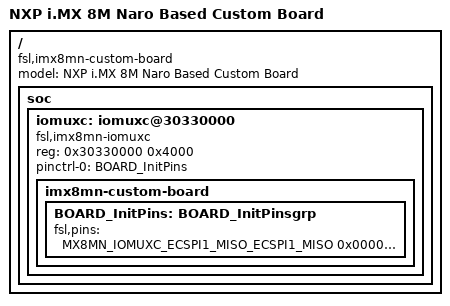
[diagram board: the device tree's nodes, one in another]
/***********************************************************************************************************************
 * This file was generated by the MCUXpresso Config Tools. Any manual edits made to this file
 * will be overwritten if the respective MCUXpresso Config Tools is used to update this file.
 **********************************************************************************************************************/

/*
 * TEXT BELOW IS USED AS SETTING FOR TOOLS *************************************
!!GlobalInfo
product: Pins v11.0
processor: MIMX8MN4xxxIZ
package_id: MIMX8MN4CVTIZ
mcu_data: ksdk2_0
processor_version: 11.0.1
power_domains: {NVCC_CLK: '1.8', NVCC_DRAM: '1.1', NVCC_ECSPI: '1.8', NVCC_ENET: '1.8', NVCC_GPIO1: '1.8', NVCC_I2C: '1.8', NVCC_JTAG: '1.8', NVCC_NAND: '1.8', NVCC_SAI2: '1.8',
  NVCC_SAI3: '1.8', NVCC_SAI5: '1.8', NVCC_SD1: '1.8', NVCC_SD2: '1.8', NVCC_SNVS_1P8: '1.8', NVCC_UART: '1.8', VDD_ANA1_1P8: '1.8', VDD_MIPI_1P8: '1.8', VDD_USB_1P8: '1.8',
  VDD_USB_3P3: '3.3'}
 * BE CAREFUL MODIFYING THIS COMMENT - IT IS YAML SETTINGS FOR TOOLS ***********
 */


/dts-v1/;

#include "skeleton.dtsi"
#include "pins-imx8mn.h"

/ {
    model = "NXP i.MX 8M Naro Based Custom Board";
    compatible = "fsl,imx8mn-custom-board", "fsl,imx8mn-evk", "fsl,imx8mn";

    soc {
        #address-cells = <1>;
        #size-cells = <1>;

        iomuxc: iomuxc@30330000 {
            compatible = "fsl,imx8mn-iomuxc";
            reg = <0x30330000 0x4000>;
        };
    };
};

&iomuxc {
    pinctrl-names = "default_iomuxc";
    pinctrl-0 = <&BOARD_InitPins>;


    imx8mn-custom-board {
        BOARD_InitPins: BOARD_InitPinsgrp {                /*!< Function assigned for the core: Cortex-A53[a53_0] */
/*
 * TEXT BELOW IS USED AS SETTING FOR TOOLS *************************************
BOARD_InitPins:
- options: {callFromInitBoot: 'false', coreID: a53_0}
- pin_list:
  - {pin_num: B27, peripheral: XTALOSC, signal: xtalosc_xtal_in_24m, pin_signal: XTALI_24M}
  - {pin_num: P27, peripheral: uSDHC3, signal: usdhc_strobe, pin_signal: NAND_CE1_B}
  - {pin_num: M27, peripheral: uSDHC3, signal: 'usdhc_data, 5', pin_signal: NAND_CE2_B}
  - {pin_num: L27, peripheral: uSDHC3, signal: 'usdhc_data, 6', pin_signal: NAND_CE3_B}
  - {pin_num: K27, peripheral: uSDHC3, signal: 'usdhc_data, 7', pin_signal: NAND_CLE}
  - {pin_num: N27, peripheral: uSDHC3, signal: 'usdhc_data, 4', pin_signal: NAND_RE_B}
  - {pin_num: R26, peripheral: uSDHC3, signal: usdhc_clk, pin_signal: NAND_WE_B}
  - {pin_num: R27, peripheral: uSDHC3, signal: usdhc_cmd, pin_signal: NAND_WP_B}
  - {pin_num: M26, peripheral: uSDHC3, signal: 'usdhc_data, 0', pin_signal: NAND_DATA04}
  - {pin_num: L26, peripheral: uSDHC3, signal: 'usdhc_data, 1', pin_signal: NAND_DATA05}
  - {pin_num: K26, peripheral: uSDHC3, signal: 'usdhc_data, 2', pin_signal: NAND_DATA06}
  - {pin_num: N26, peripheral: uSDHC3, signal: 'usdhc_data, 3', pin_signal: NAND_DATA07}
  - {pin_num: W23, peripheral: uSDHC2, signal: usdhc_clk, pin_signal: SD2_CLK}
  - {pin_num: W24, peripheral: uSDHC2, signal: usdhc_cmd, pin_signal: SD2_CMD}
  - {pin_num: AB23, peripheral: uSDHC2, signal: 'usdhc_data, 0', pin_signal: SD2_DATA0}
  - {pin_num: AB24, peripheral: uSDHC2, signal: 'usdhc_data, 1', pin_signal: SD2_DATA1}
  - {pin_num: V24, peripheral: uSDHC2, signal: 'usdhc_data, 2', pin_signal: SD2_DATA2}
  - {pin_num: V23, peripheral: uSDHC2, signal: 'usdhc_data, 3', pin_signal: SD2_DATA3}
  - {pin_num: AA27, peripheral: uSDHC2, signal: usdhc_wp, pin_signal: SD2_WP}
  - {pin_num: AA26, peripheral: uSDHC2, signal: usdhc_cd_b, pin_signal: SD2_CD_B}
  - {pin_num: Y27, peripheral: uSDHC1, signal: 'usdhc_data, 0', pin_signal: SD1_DATA0}
  - {pin_num: V27, peripheral: uSDHC1, signal: usdhc_cmd, pin_signal: SD1_CMD}
  - {pin_num: Y26, peripheral: uSDHC1, signal: 'usdhc_data, 1', pin_signal: SD1_DATA1}
  - {pin_num: T26, peripheral: uSDHC1, signal: 'usdhc_data, 3', pin_signal: SD1_DATA3}
  - {pin_num: T27, peripheral: uSDHC1, signal: 'usdhc_data, 2', pin_signal: SD1_DATA2}
  - {pin_num: U27, peripheral: uSDHC1, signal: 'usdhc_data, 4', pin_signal: SD1_DATA4}
  - {pin_num: U26, peripheral: uSDHC1, signal: 'usdhc_data, 5', pin_signal: SD1_DATA5}
  - {pin_num: W27, peripheral: uSDHC1, signal: 'usdhc_data, 6', pin_signal: SD1_DATA6}
  - {pin_num: W26, peripheral: uSDHC1, signal: 'usdhc_data, 7', pin_signal: SD1_DATA7}
  - {pin_num: V26, peripheral: uSDHC1, signal: usdhc_clk, pin_signal: SD1_CLK}
  - {pin_num: AG11, peripheral: uSDHC1, signal: usdhc_cd_b, pin_signal: GPIO1_IO06}
  - {pin_num: AF11, peripheral: uSDHC1, signal: usdhc_wp, pin_signal: GPIO1_IO07}
  - {pin_num: F26, peripheral: CJTAG, signal: jtag_tck, pin_signal: JTAG_TCK}
  - {pin_num: E27, peripheral: CJTAG, signal: jtag_tdi, pin_signal: JTAG_TDI}
  - {pin_num: E26, peripheral: CJTAG, signal: jtag_tdo, pin_signal: JTAG_TDO}
  - {pin_num: F27, peripheral: CJTAG, signal: jtag_tms, pin_signal: JTAG_TMS}
  - {pin_num: C27, peripheral: CJTAG, signal: jtag_trst_b, pin_signal: BOOT_MODE2}
  - {pin_num: E9, peripheral: I2C1, signal: i2c_scl, pin_signal: I2C1_SCL}
  - {pin_num: F9, peripheral: I2C1, signal: i2c_sda, pin_signal: I2C1_SDA}
  - {pin_num: D9, peripheral: I2C2, signal: i2c_sda, pin_signal: I2C2_SDA}
  - {pin_num: D10, peripheral: I2C2, signal: i2c_scl, pin_signal: I2C2_SCL}
  - {pin_num: F10, peripheral: I2C3, signal: i2c_sda, pin_signal: I2C3_SDA}
  - {pin_num: E10, peripheral: I2C3, signal: i2c_scl, pin_signal: I2C3_SCL}
  - {pin_num: AE27, peripheral: ENET1, signal: 'enet_rgmii_rd, 0', pin_signal: ENET_RD0}
  - {pin_num: AD27, peripheral: ENET1, signal: 'enet_rgmii_rd, 1', pin_signal: ENET_RD1}
  - {pin_num: AD26, peripheral: ENET1, signal: 'enet_rgmii_rd, 2', pin_signal: ENET_RD2}
  - {pin_num: AC26, peripheral: ENET1, signal: 'enet_rgmii_rd, 3', pin_signal: ENET_RD3}
  - {pin_num: AF26, peripheral: ENET1, signal: 'enet_rgmii_td, 1', pin_signal: ENET_TD1}
  - {pin_num: AG25, peripheral: ENET1, signal: 'enet_rgmii_td, 2', pin_signal: ENET_TD2}
  - {pin_num: AF25, peripheral: ENET1, signal: 'enet_rgmii_td, 3', pin_signal: ENET_TD3}
  - {pin_num: AG26, peripheral: ENET1, signal: 'enet_rgmii_td, 0', pin_signal: ENET_TD0}
  - {pin_num: AG24, peripheral: ENET1, signal: enet_rgmii_txc, pin_signal: ENET_TXC}
  - {pin_num: AF24, peripheral: ENET1, signal: enet_rgmii_tx_ctl, pin_signal: ENET_TX_CTL}
  - {pin_num: AF27, peripheral: ENET1, signal: enet_rgmii_rx_ctl, pin_signal: ENET_RX_CTL}
  - {pin_num: AE26, peripheral: ENET1, signal: enet_rgmii_rxc, pin_signal: ENET_RXC}
  - {pin_num: AC27, peripheral: ENET1, signal: enet_mdc, pin_signal: ENET_MDC}
  - {pin_num: AB27, peripheral: ENET1, signal: enet_mdio, pin_signal: ENET_MDIO}
  - {pin_num: A22, peripheral: USB1, signal: usb_dn, pin_signal: USB1_DN}
  - {pin_num: B22, peripheral: USB1, signal: usb_dp, pin_signal: USB1_DP}
  - {peripheral: USB2, signal: usb_dp, pin_signal: USB2_DP}
  - {peripheral: USB2, signal: usb_dn, pin_signal: USB2_DN}
  - {peripheral: USB2, signal: usb_id, pin_signal: USB2_ID}
  - {pin_num: AD9, peripheral: USB1, signal: usb_otg_oc, pin_signal: GPIO1_IO13}
  - {pin_num: AB10, peripheral: USB1, signal: usb_otg_pwr, pin_signal: GPIO1_IO12}
  - {pin_num: F22, peripheral: USB1, signal: usb_vbus, pin_signal: USB1_VBUS}
  - {pin_num: D22, peripheral: USB1, signal: usb_id, pin_signal: USB1_ID}
  - {peripheral: USB2, signal: usb_vbus, pin_signal: USB2_VBUS}
  - {pin_num: AC9, peripheral: USB2, signal: usb_otg_pwr, pin_signal: GPIO1_IO14}
  - {pin_num: AB9, peripheral: USB2, signal: usb_otg_oc, pin_signal: GPIO1_IO15}
  - {pin_num: A7, peripheral: ECSPI1, signal: ecspi_miso, pin_signal: ECSPI1_MISO}
  - {pin_num: B7, peripheral: ECSPI1, signal: ecspi_mosi, pin_signal: ECSPI1_MOSI}
  - {pin_num: D6, peripheral: ECSPI1, signal: ecspi_sclk, pin_signal: ECSPI1_SCLK, PE: Enabled}
  - {pin_num: B6, peripheral: ECSPI1, signal: 'ecspi_ss, 0', pin_signal: ECSPI1_SS0}
  - {pin_num: N22, peripheral: QSPI, signal: qspi_a_sclk, pin_signal: NAND_ALE}
  - {pin_num: N24, peripheral: QSPI, signal: qspi_a_ss0_b, pin_signal: NAND_CE0_B}
  - {pin_num: P23, peripheral: QSPI, signal: 'qspi_a_data, 0', pin_signal: NAND_DATA00}
  - {pin_num: K24, peripheral: QSPI, signal: 'qspi_a_data, 1', pin_signal: NAND_DATA01}
  - {pin_num: K23, peripheral: QSPI, signal: 'qspi_a_data, 2', pin_signal: NAND_DATA02}
  - {pin_num: N23, peripheral: QSPI, signal: 'qspi_a_data, 3', pin_signal: NAND_DATA03}
  - {pin_num: A16, peripheral: MIPI_CSI, signal: mipi_csi_clk_n, pin_signal: MIPI_CSI_CLK_N}
  - {pin_num: B16, peripheral: MIPI_CSI, signal: mipi_csi_clk_p, pin_signal: MIPI_CSI_CLK_P}
  - {pin_num: A14, peripheral: MIPI_CSI, signal: mipi_csi_d0_n, pin_signal: MIPI_CSI_D0_N}
  - {pin_num: B14, peripheral: MIPI_CSI, signal: mipi_csi_d0_p, pin_signal: MIPI_CSI_D0_P}
  - {pin_num: A15, peripheral: MIPI_CSI, signal: mipi_csi_d1_n, pin_signal: MIPI_CSI_D1_N}
  - {pin_num: B15, peripheral: MIPI_CSI, signal: mipi_csi_d1_p, pin_signal: MIPI_CSI_D1_P}
  - {pin_num: A17, peripheral: MIPI_CSI, signal: mipi_csi_d2_n, pin_signal: MIPI_CSI_D2_N}
  - {pin_num: B17, peripheral: MIPI_CSI, signal: mipi_csi_d2_p, pin_signal: MIPI_CSI_D2_P}
  - {pin_num: A18, peripheral: MIPI_CSI, signal: mipi_csi_d3_n, pin_signal: MIPI_CSI_D3_N}
  - {pin_num: B18, peripheral: MIPI_CSI, signal: mipi_csi_d3_p, pin_signal: MIPI_CSI_D3_P}
  - {pin_num: A11, peripheral: MIPI_DSI, signal: mipi_dsi_clk_n, pin_signal: MIPI_DSI_CLK_N}
  - {pin_num: B11, peripheral: MIPI_DSI, signal: mipi_dsi_clk_p, pin_signal: MIPI_DSI_CLK_P}
  - {pin_num: A9, peripheral: MIPI_DSI, signal: mipi_dsi_d0_n, pin_signal: MIPI_DSI_D0_N}
  - {pin_num: B9, peripheral: MIPI_DSI, signal: mipi_dsi_d0_p, pin_signal: MIPI_DSI_D0_P}
  - {pin_num: A10, peripheral: MIPI_DSI, signal: mipi_dsi_d1_n, pin_signal: MIPI_DSI_D1_N}
  - {pin_num: B10, peripheral: MIPI_DSI, signal: mipi_dsi_d1_p, pin_signal: MIPI_DSI_D1_P}
  - {pin_num: A12, peripheral: MIPI_DSI, signal: mipi_dsi_d2_n, pin_signal: MIPI_DSI_D2_N}
  - {pin_num: B12, peripheral: MIPI_DSI, signal: mipi_dsi_d2_p, pin_signal: MIPI_DSI_D2_P}
  - {pin_num: A13, peripheral: MIPI_DSI, signal: mipi_dsi_d3_n, pin_signal: MIPI_DSI_D3_N}
  - {pin_num: B13, peripheral: MIPI_DSI, signal: mipi_dsi_d3_p, pin_signal: MIPI_DSI_D3_P}
  - {pin_num: D15, peripheral: MIPI_DSI, signal: mipi_dsi_rext, pin_signal: MIPI_VREG_CAP}
  - {peripheral: PCIE1, signal: pcie_rxn_n, pin_signal: PCIE_RXN_N}
  - {peripheral: PCIE1, signal: pcie_rxn_p, pin_signal: PCIE_RXN_P}
  - {peripheral: PCIE1, signal: pcie_txn_n, pin_signal: PCIE_TXN_N}
  - {peripheral: PCIE1, signal: pcie_txn_p, pin_signal: PCIE_TXN_P}
  - {peripheral: PCIE1, signal: pcie_ref_pad_clk_n, pin_signal: PCIE_REF_PAD_CLK_N}
  - {peripheral: PCIE1, signal: pcie_ref_pad_clk_p, pin_signal: PCIE_REF_PAD_CLK_P}
  - {pin_num: E14, peripheral: UART1, signal: uart_rx, pin_signal: UART1_RXD}
  - {pin_num: F13, peripheral: UART1, signal: uart_tx, pin_signal: UART1_TXD}
  - {pin_num: F15, peripheral: UART2, signal: uart_rx, pin_signal: UART2_RXD}
  - {pin_num: E15, peripheral: UART2, signal: uart_tx, pin_signal: UART2_TXD}
  - {pin_num: D18, peripheral: UART3, signal: uart_tx, pin_signal: UART3_TXD}
  - {pin_num: E18, peripheral: UART3, signal: uart_rx, pin_signal: UART3_RXD}
  - {pin_num: F19, peripheral: UART2, signal: uart_cts_b, pin_signal: UART4_RXD}
  - {pin_num: F18, peripheral: UART2, signal: uart_rts_b, pin_signal: UART4_TXD}
  - {pin_num: AF9, peripheral: PWM3, signal: pwm_out, pin_signal: SPDIF_TX}
  - {pin_num: A4, peripheral: DRAM, signal: 'dram_dm, 0', pin_signal: DRAM_DM0}
  - {pin_num: F1, peripheral: DRAM, signal: 'dram_dm, 1', pin_signal: DRAM_DM1}
  - {peripheral: DRAM, signal: 'dram_dm, 2', pin_signal: DRAM_DM2}
  - {peripheral: DRAM, signal: 'dram_dm, 3', pin_signal: DRAM_DM3}
  - {pin_num: A5, peripheral: DRAM, signal: 'dram_dq, 00', pin_signal: DRAM_DQ00}
  - {pin_num: B5, peripheral: DRAM, signal: 'dram_dq, 01', pin_signal: DRAM_DQ01}
  - {pin_num: D2, peripheral: DRAM, signal: 'dram_dq, 02', pin_signal: DRAM_DQ02}
  - {pin_num: D1, peripheral: DRAM, signal: 'dram_dq, 03', pin_signal: DRAM_DQ03}
  - {pin_num: C1, peripheral: DRAM, signal: 'dram_dq, 04', pin_signal: DRAM_DQ04}
  - {pin_num: B1, peripheral: DRAM, signal: 'dram_dq, 05', pin_signal: DRAM_DQ05}
  - {pin_num: A3, peripheral: DRAM, signal: 'dram_dq, 06', pin_signal: DRAM_DQ06}
  - {pin_num: B4, peripheral: DRAM, signal: 'dram_dq, 07', pin_signal: DRAM_DQ07}
  - {pin_num: F2, peripheral: DRAM, signal: 'dram_dq, 08', pin_signal: DRAM_DQ08}
  - {pin_num: G2, peripheral: DRAM, signal: 'dram_dq, 09', pin_signal: DRAM_DQ09}
  - {pin_num: J1, peripheral: DRAM, signal: 'dram_dq, 10', pin_signal: DRAM_DQ10}
  - {pin_num: J2, peripheral: DRAM, signal: 'dram_dq, 11', pin_signal: DRAM_DQ11}
  - {pin_num: K2, peripheral: DRAM, signal: 'dram_dq, 12', pin_signal: DRAM_DQ12}
  - {pin_num: K1, peripheral: DRAM, signal: 'dram_dq, 13', pin_signal: DRAM_DQ13}
  - {pin_num: E1, peripheral: DRAM, signal: 'dram_dq, 14', pin_signal: DRAM_DQ14}
  - {pin_num: E2, peripheral: DRAM, signal: 'dram_dq, 15', pin_signal: DRAM_DQ15}
  - {peripheral: DRAM, signal: 'dram_dq, 16', pin_signal: DRAM_DQ16}
  - {peripheral: DRAM, signal: 'dram_dq, 17', pin_signal: DRAM_DQ17}
  - {peripheral: DRAM, signal: 'dram_dq, 18', pin_signal: DRAM_DQ18}
  - {peripheral: DRAM, signal: 'dram_dq, 19', pin_signal: DRAM_DQ19}
  - {peripheral: DRAM, signal: 'dram_dq, 20', pin_signal: DRAM_DQ20}
  - {peripheral: DRAM, signal: 'dram_dq, 21', pin_signal: DRAM_DQ21}
  - {peripheral: DRAM, signal: 'dram_dq, 23', pin_signal: DRAM_DQ23}
  - {peripheral: DRAM, signal: 'dram_dq, 22', pin_signal: DRAM_DQ22}
  - {peripheral: DRAM, signal: 'dram_dq, 24', pin_signal: DRAM_DQ24}
  - {peripheral: DRAM, signal: 'dram_dq, 25', pin_signal: DRAM_DQ25}
  - {peripheral: DRAM, signal: 'dram_dq, 26', pin_signal: DRAM_DQ26}
  - {peripheral: DRAM, signal: 'dram_dq, 27', pin_signal: DRAM_DQ27}
  - {peripheral: DRAM, signal: 'dram_dq, 28', pin_signal: DRAM_DQ28}
  - {peripheral: DRAM, signal: 'dram_dq, 29', pin_signal: DRAM_DQ29}
  - {peripheral: DRAM, signal: 'dram_dq, 30', pin_signal: DRAM_DQ30}
  - {peripheral: DRAM, signal: 'dram_dq, 31', pin_signal: DRAM_DQ31}
  - {peripheral: DRAM, signal: dram_dqs3_p, pin_signal: DRAM_DQS3_P}
  - {peripheral: DRAM, signal: dram_dqs3_n, pin_signal: DRAM_DQS3_N}
  - {peripheral: DRAM, signal: dram_dqs2_p, pin_signal: DRAM_DQS2_P}
  - {pin_num: G1, peripheral: DRAM, signal: dram_dqs1_p, pin_signal: DRAM_DQS1_P}
  - {pin_num: B2, peripheral: DRAM, signal: dram_dqs0_n, pin_signal: DRAM_DQS0_N}
  - {pin_num: A2, peripheral: DRAM, signal: dram_dqs0_p, pin_signal: DRAM_DQS0_P}
  - {pin_num: H1, peripheral: DRAM, signal: dram_dqs1_n, pin_signal: DRAM_DQS1_N}
  - {peripheral: DRAM, signal: dram_dqs2_n, pin_signal: DRAM_DQS2_N}
  - {pin_num: R1, peripheral: DRAM, signal: dram_reset_n, pin_signal: DRAM_RESET_N}
  - {pin_num: P1, peripheral: DRAM, signal: dram_vref, pin_signal: DRAM_VREF}
  - {pin_num: P2, peripheral: DRAM, signal: dram_zn, pin_signal: DRAM_ZN}
  - {pin_num: R2, peripheral: DRAM, signal: dram_alert_n, pin_signal: DRAM_ALERT_N}
  - {pin_num: F4, peripheral: DRAM, signal: 'dram_ac, 00', pin_signal: DRAM_AC00}
  - {pin_num: F5, peripheral: DRAM, signal: 'dram_ac, 01', pin_signal: DRAM_AC01}
  - {pin_num: K4, peripheral: DRAM, signal: 'dram_ac, 02', pin_signal: DRAM_AC02}
  - {pin_num: J4, peripheral: DRAM, signal: 'dram_ac, 03', pin_signal: DRAM_AC03}
  - {pin_num: L2, peripheral: DRAM, signal: 'dram_ac, 04', pin_signal: DRAM_AC04}
  - {pin_num: L1, peripheral: DRAM, signal: 'dram_ac, 05', pin_signal: DRAM_AC05}
  - {pin_num: J6, peripheral: DRAM, signal: 'dram_ac, 08', pin_signal: DRAM_AC08}
  - {pin_num: K6, peripheral: DRAM, signal: 'dram_ac, 09', pin_signal: DRAM_AC09}
  - {pin_num: E4, peripheral: DRAM, signal: 'dram_ac, 10', pin_signal: DRAM_AC10}
  - {pin_num: D5, peripheral: DRAM, signal: 'dram_ac, 11', pin_signal: DRAM_AC11}
  - {pin_num: N4, peripheral: DRAM, signal: 'dram_ac, 12', pin_signal: DRAM_AC12}
  - {pin_num: N5, peripheral: DRAM, signal: 'dram_ac, 13', pin_signal: DRAM_AC13}
  - {pin_num: AB4, peripheral: DRAM, signal: 'dram_ac, 20', pin_signal: DRAM_AC20}
  - {pin_num: AB5, peripheral: DRAM, signal: 'dram_ac, 21', pin_signal: DRAM_AC21}
  - {pin_num: W4, peripheral: DRAM, signal: 'dram_ac, 22', pin_signal: DRAM_AC22}
  - {pin_num: V4, peripheral: DRAM, signal: 'dram_ac, 23', pin_signal: DRAM_AC23}
  - {pin_num: U2, peripheral: DRAM, signal: 'dram_ac, 24', pin_signal: DRAM_AC24}
  - {pin_num: U1, peripheral: DRAM, signal: 'dram_ac, 25', pin_signal: DRAM_AC25}
  - {pin_num: W6, peripheral: DRAM, signal: 'dram_ac, 28', pin_signal: DRAM_AC28}
  - {pin_num: V6, peripheral: DRAM, signal: 'dram_ac, 29', pin_signal: DRAM_AC29}
  - {pin_num: AC4, peripheral: DRAM, signal: 'dram_ac, 30', pin_signal: DRAM_AC30}
  - {pin_num: AD5, peripheral: DRAM, signal: 'dram_ac, 31', pin_signal: DRAM_AC31}
  - {pin_num: R4, peripheral: DRAM, signal: 'dram_ac, 32', pin_signal: DRAM_AC32}
  - {pin_num: R5, peripheral: DRAM, signal: 'dram_ac, 33', pin_signal: DRAM_AC33}
  - {pin_num: E6, peripheral: UART4, signal: uart_rx, pin_signal: ECSPI2_SCLK}
  - {pin_num: B8, peripheral: UART4, signal: uart_tx, pin_signal: ECSPI2_MOSI}
  - {pin_num: AF8, peripheral: PWM1, signal: pwm_out, pin_signal: SPDIF_EXT_CLK}
  - {pin_num: AG9, peripheral: PWM2, signal: pwm_out, pin_signal: SPDIF_RX}
  - {peripheral: PCIE1, signal: pcie_resref, pin_signal: PCIE_RESREF}
  - {pin_num: D13, peripheral: I2C4, signal: i2c_scl, pin_signal: I2C4_SCL}
  - {pin_num: E13, peripheral: I2C4, signal: i2c_sda, pin_signal: I2C4_SDA}
  - {pin_num: AG12, peripheral: uSDHC2, signal: usdhc_vselect, pin_signal: GPIO1_IO04}
  - {pin_num: E24, peripheral: CCM, signal: ccm_pmic_stby_req, pin_signal: PMIC_STBY_REQ}
  - {pin_num: A24, peripheral: SNVS, signal: snvs_pmic_on_req, pin_signal: PMIC_ON_REQ}
  - {pin_num: B24, peripheral: SNVS, signal: snvs_por_b, pin_signal: POR_B}
  - {pin_num: F24, peripheral: SNVS, signal: snvs_rtc_reset_b, pin_signal: RTC_RESET_B}
  - {pin_num: A26, peripheral: SNVS, signal: snvs_rtc, pin_signal: RTC_XTALI}
  - {pin_num: H26, peripheral: XTALOSC, signal: 'xtalosc_clkout, 1', pin_signal: CLKOUT1}
  - {pin_num: H27, peripheral: XTALOSC, signal: 'xtalosc_clkin, 1', pin_signal: CLKIN1}
  - {pin_num: R23, peripheral: uSDHC1, signal: usdhc_reset_b, pin_signal: SD1_RESET_B}
  - {pin_num: AB26, peripheral: uSDHC2, signal: usdhc_reset_b, pin_signal: SD2_RESET_B}
  - {pin_num: P26, peripheral: uSDHC3, signal: usdhc_reset_b, pin_signal: NAND_READY_B}
  - {pin_num: AG13, peripheral: WDOG1, signal: wdog_wdog_b, pin_signal: GPIO1_IO02}
  - {pin_num: AD19, peripheral: SAI5, signal: sai_mclk, pin_signal: SAI2_MCLK}
  - {pin_num: AF7, peripheral: SAI5, signal: 'sai_rx_data, 0', pin_signal: SAI3_RXD}
  - {pin_num: AC6, peripheral: SAI5, signal: 'sai_rx_data, 1', pin_signal: SAI3_TXFS}
  - {pin_num: AB22, peripheral: SAI5, signal: sai_tx_bclk, pin_signal: SAI2_RXC}
  - {pin_num: AC13, peripheral: SAI5, signal: 'sai_tx_data, 0', pin_signal: SAI5_RXD3}
  - {pin_num: AC19, peripheral: SAI5, signal: 'sai_tx_data, 1', pin_signal: SAI2_RXFS}
  - {pin_num: AC14, peripheral: SAI5, signal: sai_tx_sync, pin_signal: SAI5_RXD1}
  - {pin_num: A8, peripheral: UART4, signal: uart_cts_b, pin_signal: ECSPI2_MISO}
  - {pin_num: A6, peripheral: UART4, signal: uart_rts_b, pin_signal: ECSPI2_SS0}
  - {pin_num: AD6, peripheral: PWM4, signal: pwm_out, pin_signal: SAI3_MCLK}
  - {pin_num: AG6, peripheral: GPIO5, signal: 'gpio_io, 00', pin_signal: SAI3_TXC}
  - {pin_num: AF6, peripheral: GPIO5, signal: 'gpio_io, 01', pin_signal: SAI3_TXD}
  - {pin_num: AG14, peripheral: CCM, signal: ccm_enet_phy_ref_clk_root, pin_signal: GPIO1_IO00}
  - {pin_num: AF14, peripheral: CCM, signal: 'ccm_ext_clk, 2', pin_signal: GPIO1_IO01}
  - {pin_num: A25, peripheral: SNVS, signal: snvs_onoff, pin_signal: ONOFF}
  - {pin_num: D27, peripheral: CJTAG, signal: jtag_mode, pin_signal: JTAG_MOD}
  - {pin_num: D26, peripheral: TCU, signal: tcu_test_mode, pin_signal: BOOT_MODE3}
  - {pin_num: AF13, peripheral: GPIO1, signal: 'gpio_io, 03', pin_signal: GPIO1_IO03}
  - {pin_num: AF12, peripheral: GPIO1, signal: 'gpio_io, 05', pin_signal: GPIO1_IO05}
  - {pin_num: AG10, peripheral: GPIO1, signal: 'gpio_io, 08', pin_signal: GPIO1_IO08}
  - {pin_num: AF10, peripheral: GPIO1, signal: 'gpio_io, 09', pin_signal: GPIO1_IO09}
  - {pin_num: AD10, peripheral: GPIO1, signal: 'gpio_io, 10', pin_signal: GPIO1_IO10}
  - {pin_num: AC10, peripheral: GPIO1, signal: 'gpio_io, 11', pin_signal: GPIO1_IO11}
  - {peripheral: GPIO4, signal: 'gpio_io, 20', pin_signal: SAI1_MCLK}
  - {peripheral: GPIO4, signal: 'gpio_io, 01', pin_signal: SAI1_RXC}
  - {peripheral: SRC, signal: 'src_boot_cfg, 0', pin_signal: SAI1_RXD0}
  - {peripheral: SRC, signal: 'src_boot_cfg, 1', pin_signal: SAI1_RXD1}
  - {peripheral: SRC, signal: 'src_boot_cfg, 2', pin_signal: SAI1_RXD2}
  - {peripheral: SRC, signal: 'src_boot_cfg, 3', pin_signal: SAI1_RXD3}
  - {peripheral: GPIO4, signal: 'gpio_io, 08', pin_signal: SAI1_RXD6}
  - {peripheral: GPIO4, signal: 'gpio_io, 00', pin_signal: SAI1_RXFS}
  - {peripheral: GPIO4, signal: 'gpio_io, 11', pin_signal: SAI1_TXC}
  - {peripheral: GPIO4, signal: 'gpio_io, 10', pin_signal: SAI1_TXFS}
  - {peripheral: SRC, signal: 'src_boot_cfg, 5', pin_signal: SAI1_RXD5}
  - {peripheral: SRC, signal: 'src_boot_cfg, 7', pin_signal: SAI1_RXD7}
  - {peripheral: SRC, signal: 'src_boot_cfg, 10', pin_signal: SAI1_TXD2}
  - {peripheral: SRC, signal: 'src_boot_cfg, 11', pin_signal: SAI1_TXD3}
  - {peripheral: SRC, signal: 'src_boot_cfg, 12', pin_signal: SAI1_TXD4}
  - {peripheral: SRC, signal: 'src_boot_cfg, 13', pin_signal: SAI1_TXD5}
  - {peripheral: SRC, signal: 'src_boot_cfg, 14', pin_signal: SAI1_TXD6}
  - {peripheral: SRC, signal: 'src_boot_cfg, 15', pin_signal: SAI1_TXD7}
  - {pin_num: AC24, peripheral: GPIO4, signal: 'gpio_io, 23', pin_signal: SAI2_RXD0}
  - {pin_num: AD23, peripheral: GPIO4, signal: 'gpio_io, 24', pin_signal: SAI2_TXFS}
  - {pin_num: AD22, peripheral: GPIO4, signal: 'gpio_io, 25', pin_signal: SAI2_TXC}
  - {pin_num: AC22, peripheral: GPIO4, signal: 'gpio_io, 26', pin_signal: SAI2_TXD0}
  - {pin_num: AG7, peripheral: GPIO4, signal: 'gpio_io, 29', pin_signal: SAI3_RXC}
  - {pin_num: AG8, peripheral: GPIO4, signal: 'gpio_io, 28', pin_signal: SAI3_RXFS}
  - {pin_num: AD15, peripheral: GPIO3, signal: 'gpio_io, 25', pin_signal: SAI5_MCLK}
  - {pin_num: AC15, peripheral: GPIO3, signal: 'gpio_io, 20', pin_signal: SAI5_RXC}
  - {pin_num: AD18, peripheral: GPIO3, signal: 'gpio_io, 21', pin_signal: SAI5_RXD0}
  - {pin_num: AD13, peripheral: GPIO3, signal: 'gpio_io, 23', pin_signal: SAI5_RXD2}
  - {pin_num: AB15, peripheral: GPIO3, signal: 'gpio_io, 19', pin_signal: SAI5_RXFS}
  - {pin_num: G26, peripheral: SRC, signal: 'src_boot_mode, 0', pin_signal: BOOT_MODE0}
  - {pin_num: G27, peripheral: SRC, signal: 'src_boot_mode, 1', pin_signal: BOOT_MODE1}
  - {peripheral: SRC, signal: 'src_boot_cfg, 9', pin_signal: SAI1_TXD1}
  - {peripheral: SRC, signal: 'src_boot_cfg, 8', pin_signal: SAI1_TXD0}
  - {peripheral: SRC, signal: 'src_boot_cfg, 4', pin_signal: SAI1_RXD4}
 * BE CAREFUL MODIFYING THIS COMMENT - IT IS YAML SETTINGS FOR TOOLS ***********
 */
            fsl,pins = <
                MX8MN_IOMUXC_ECSPI1_MISO_ECSPI1_MISO       0x00000116
                MX8MN_IOMUXC_ECSPI1_MOSI_ECSPI1_MOSI       0x00000116
                MX8MN_IOMUXC_ECSPI1_SCLK_ECSPI1_SCLK       0x00000116
                MX8MN_IOMUXC_ECSPI1_SS0_ECSPI1_SS0         0x00000116
                MX8MN_IOMUXC_ECSPI2_MISO_UART4_DCE_CTS_B   0x00000116
                MX8MN_IOMUXC_ECSPI2_MOSI_UART4_DCE_TX      0x00000116
                MX8MN_IOMUXC_ECSPI2_SCLK_UART4_DCE_RX      0x00000116
                MX8MN_IOMUXC_ECSPI2_SS0_UART4_DCE_RTS_B    0x00000116
                MX8MN_IOMUXC_ENET_MDC_ENET1_MDC            0x00000116
                MX8MN_IOMUXC_ENET_MDIO_ENET1_MDIO          0x00000116
                MX8MN_IOMUXC_ENET_RD0_ENET1_RGMII_RD0      0x00000116
                MX8MN_IOMUXC_ENET_RD1_ENET1_RGMII_RD1      0x00000116
                MX8MN_IOMUXC_ENET_RD2_ENET1_RGMII_RD2      0x00000116
                MX8MN_IOMUXC_ENET_RD3_ENET1_RGMII_RD3      0x00000116
                MX8MN_IOMUXC_ENET_RXC_ENET1_RGMII_RXC      0x00000116
                MX8MN_IOMUXC_ENET_RX_CTL_ENET1_RGMII_RX_CTL 0x00000116
                MX8MN_IOMUXC_ENET_TD0_ENET1_RGMII_TD0      0x00000116
                MX8MN_IOMUXC_ENET_TD1_ENET1_RGMII_TD1      0x00000116
                MX8MN_IOMUXC_ENET_TD2_ENET1_RGMII_TD2      0x00000116
                MX8MN_IOMUXC_ENET_TD3_ENET1_RGMII_TD3      0x00000116
                MX8MN_IOMUXC_ENET_TXC_ENET1_RGMII_TXC      0x00000116
                MX8MN_IOMUXC_ENET_TX_CTL_ENET1_RGMII_TX_CTL 0x00000116
                MX8MN_IOMUXC_GPIO1_IO00_CCMSRCGPCMIX_ENET_PHY_REF_CLK_ROOT 0x00000116
                MX8MN_IOMUXC_GPIO1_IO01_CCMSRCGPCMIX_EXT_CLK2 0x00000116
                MX8MN_IOMUXC_GPIO1_IO02_WDOG1_WDOG_B       0x00000156
                MX8MN_IOMUXC_GPIO1_IO03_GPIO1_IO3          0x00000116
                MX8MN_IOMUXC_GPIO1_IO04_USDHC2_VSELECT     0x00000116
                MX8MN_IOMUXC_GPIO1_IO05_GPIO1_IO5          0x00000156
                MX8MN_IOMUXC_GPIO1_IO06_USDHC1_CD_B        0x00000116
                MX8MN_IOMUXC_GPIO1_IO07_USDHC1_WP          0x00000116
                MX8MN_IOMUXC_GPIO1_IO08_GPIO1_IO8          0x00000116
                MX8MN_IOMUXC_GPIO1_IO09_GPIO1_IO9          0x00000116
                MX8MN_IOMUXC_GPIO1_IO10_GPIO1_IO10         0x00000116
                MX8MN_IOMUXC_GPIO1_IO11_GPIO1_IO11         0x00000116
                MX8MN_IOMUXC_GPIO1_IO12_USB1_OTG_PWR       0x00000116
                MX8MN_IOMUXC_GPIO1_IO13_USB1_OTG_OC        0x00000116
                MX8MN_IOMUXC_I2C1_SCL_I2C1_SCL             0x00000116
                MX8MN_IOMUXC_I2C1_SDA_I2C1_SDA             0x00000116
                MX8MN_IOMUXC_I2C2_SCL_I2C2_SCL             0x00000116
                MX8MN_IOMUXC_I2C2_SDA_I2C2_SDA             0x00000116
                MX8MN_IOMUXC_I2C3_SCL_I2C3_SCL             0x00000116
                MX8MN_IOMUXC_I2C3_SDA_I2C3_SDA             0x00000116
                MX8MN_IOMUXC_I2C4_SCL_I2C4_SCL             0x00000116
                MX8MN_IOMUXC_I2C4_SDA_I2C4_SDA             0x00000116
                MX8MN_IOMUXC_NAND_ALE_QSPI_A_SCLK          0x00000116
                MX8MN_IOMUXC_NAND_CE0_B_QSPI_A_SS0_B       0x00000116
                MX8MN_IOMUXC_NAND_CE1_B_USDHC3_STROBE      0x00000116
                MX8MN_IOMUXC_NAND_CE2_B_USDHC3_DATA5       0x00000116
                MX8MN_IOMUXC_NAND_CE3_B_USDHC3_DATA6       0x00000116
                MX8MN_IOMUXC_NAND_CLE_USDHC3_DATA7         0x00000116
                MX8MN_IOMUXC_NAND_DATA00_QSPI_A_DATA0      0x00000116
                MX8MN_IOMUXC_NAND_DATA01_QSPI_A_DATA1      0x00000116
                MX8MN_IOMUXC_NAND_DATA02_QSPI_A_DATA2      0x00000116
                MX8MN_IOMUXC_NAND_DATA03_QSPI_A_DATA3      0x00000116
                MX8MN_IOMUXC_NAND_DATA04_USDHC3_DATA0      0x00000116
                MX8MN_IOMUXC_NAND_DATA05_USDHC3_DATA1      0x00000116
                MX8MN_IOMUXC_NAND_DATA06_USDHC3_DATA2      0x00000116
                MX8MN_IOMUXC_NAND_DATA07_USDHC3_DATA3      0x00000116
                MX8MN_IOMUXC_NAND_READY_B_USDHC3_RESET_B   0x00000116
                MX8MN_IOMUXC_NAND_RE_B_USDHC3_DATA4        0x00000116
                MX8MN_IOMUXC_NAND_WE_B_USDHC3_CLK          0x00000116
                MX8MN_IOMUXC_NAND_WP_B_USDHC3_CMD          0x00000116
                MX8MN_IOMUXC_SAI2_MCLK_SAI5_MCLK           0x00000116
                MX8MN_IOMUXC_SAI2_RXC_SAI5_TX_BCLK         0x00000116
                MX8MN_IOMUXC_SAI2_RXD0_GPIO4_IO23          0x00000116
                MX8MN_IOMUXC_SAI2_RXFS_SAI5_TX_DATA1       0x00000116
                MX8MN_IOMUXC_SAI2_TXC_GPIO4_IO25           0x00000116
                MX8MN_IOMUXC_SAI2_TXD0_GPIO4_IO26          0x00000116
                MX8MN_IOMUXC_SAI2_TXFS_GPIO4_IO24          0x00000116
                MX8MN_IOMUXC_SAI3_MCLK_PWM4_OUT            0x00000116
                MX8MN_IOMUXC_SAI3_RXC_GPIO4_IO29           0x00000116
                MX8MN_IOMUXC_SAI3_RXD_SAI5_RX_DATA0        0x00000116
                MX8MN_IOMUXC_SAI3_RXFS_GPIO4_IO28          0x00000116
                MX8MN_IOMUXC_SAI3_TXC_GPIO5_IO0            0x00000116
                MX8MN_IOMUXC_SAI3_TXD_GPIO5_IO1            0x00000116
                MX8MN_IOMUXC_SAI3_TXFS_SAI5_RX_DATA1       0x00000116
                MX8MN_IOMUXC_SAI5_MCLK_GPIO3_IO25          0x00000116
                MX8MN_IOMUXC_SAI5_RXC_GPIO3_IO20           0x00000116
                MX8MN_IOMUXC_SAI5_RXD0_GPIO3_IO21          0x00000116
                MX8MN_IOMUXC_SAI5_RXD1_SAI5_TX_SYNC        0x00000116
                MX8MN_IOMUXC_SAI5_RXD2_GPIO3_IO23          0x00000116
                MX8MN_IOMUXC_SAI5_RXD3_SAI5_TX_DATA0       0x00000116
                MX8MN_IOMUXC_SAI5_RXFS_GPIO3_IO19          0x00000116
                MX8MN_IOMUXC_SD1_CLK_USDHC1_CLK            0x00000116
                MX8MN_IOMUXC_SD1_CMD_USDHC1_CMD            0x00000116
                MX8MN_IOMUXC_SD1_DATA0_USDHC1_DATA0        0x00000116
                MX8MN_IOMUXC_SD1_DATA1_USDHC1_DATA1        0x00000116
                MX8MN_IOMUXC_SD1_DATA2_USDHC1_DATA2        0x00000116
                MX8MN_IOMUXC_SD1_DATA3_USDHC1_DATA3        0x00000116
                MX8MN_IOMUXC_SD1_DATA4_USDHC1_DATA4        0x00000116
                MX8MN_IOMUXC_SD1_DATA5_USDHC1_DATA5        0x00000116
                MX8MN_IOMUXC_SD1_DATA6_USDHC1_DATA6        0x00000116
                MX8MN_IOMUXC_SD1_DATA7_USDHC1_DATA7        0x00000116
                MX8MN_IOMUXC_SD1_RESET_B_USDHC1_RESET_B    0x00000116
                MX8MN_IOMUXC_SD2_CD_B_USDHC2_CD_B          0x00000116
                MX8MN_IOMUXC_SD2_CLK_USDHC2_CLK            0x00000116
                MX8MN_IOMUXC_SD2_CMD_USDHC2_CMD            0x00000116
                MX8MN_IOMUXC_SD2_DATA0_USDHC2_DATA0        0x00000116
                MX8MN_IOMUXC_SD2_DATA1_USDHC2_DATA1        0x00000116
                MX8MN_IOMUXC_SD2_DATA2_USDHC2_DATA2        0x00000116
                MX8MN_IOMUXC_SD2_DATA3_USDHC2_DATA3        0x00000116
                MX8MN_IOMUXC_SD2_RESET_B_USDHC2_RESET_B    0x00000116
                MX8MN_IOMUXC_SD2_WP_USDHC2_WP              0x00000116
                MX8MN_IOMUXC_SPDIF_EXT_CLK_PWM1_OUT        0x00000116
                MX8MN_IOMUXC_SPDIF_RX_PWM2_OUT             0x00000116
                MX8MN_IOMUXC_SPDIF_TX_PWM3_OUT             0x00000116
                MX8MN_IOMUXC_UART1_RXD_UART1_DCE_RX        0x00000116
                MX8MN_IOMUXC_UART1_TXD_UART1_DCE_TX        0x00000116
                MX8MN_IOMUXC_UART2_RXD_UART2_DCE_RX        0x00000116
                MX8MN_IOMUXC_UART2_TXD_UART2_DCE_TX        0x00000116
                MX8MN_IOMUXC_UART3_RXD_UART3_DCE_RX        0x00000116
                MX8MN_IOMUXC_UART3_TXD_UART3_DCE_TX        0x00000116
                MX8MN_IOMUXC_UART4_RXD_UART2_DCE_CTS_B     0x00000116
                MX8MN_IOMUXC_UART4_TXD_UART2_DCE_RTS_B     0x00000116
            >;
        };
    };
};

/***********************************************************************************************************************
 * EOF
 **********************************************************************************************************************/
